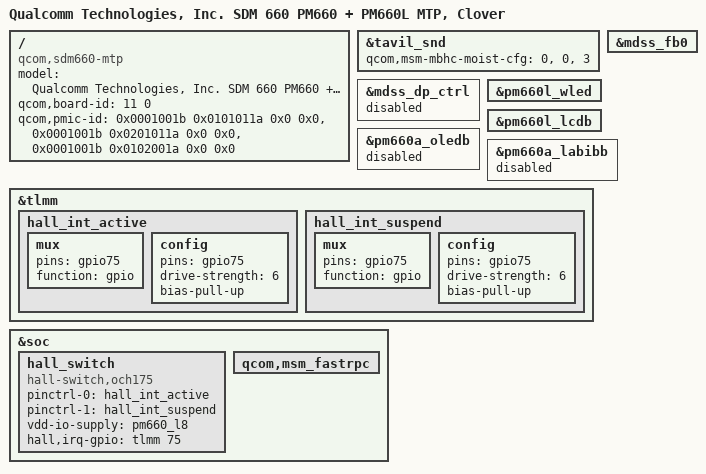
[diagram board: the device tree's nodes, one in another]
/dts-v1/;

#include "sdm660.dtsi"
#include "sdm660-mtp.dtsi"
#include "sdm660-mtp-clover.dtsi"
#include "sdm660-internal-codec.dtsi"

/ {
	model = "Qualcomm Technologies, Inc. SDM 660 PM660 + PM660L MTP, Clover";
	compatible = "qcom,sdm660-mtp", "qcom,sdm660", "qcom,mtp";
	qcom,board-id = <11 0>;
	qcom,pmic-id = <0x0001001b 0x0101011a 0x0 0x0>,
			<0x0001001b 0x0201011a 0x0 0x0>,
			<0x0001001b 0x0102001a 0x0 0x0>;
};

&tavil_snd {
	qcom,msm-mbhc-moist-cfg = <0>, <0>, <3>;
};

&mdss_dp_ctrl {
	status="disabled";
};

&mdss_fb0 {
	/delete-property/ qcom,mdss-mixer-swap;
};

/* Enable WLED */
&pm660l_wled {
	status = "okay";
};

/* Enable LCDB */
&pm660l_lcdb {
	status = "okay";
};

/* Disable OLEDB */
&pm660a_oledb {
	status = "disabled";
};

/* Disable LABIBB */
&pm660a_labibb {
	status = "disable";
};

&tlmm {
	hall_int_active:hall_int_active {
		mux {
			pins = "gpio75";
			function = "gpio";
		};

		config {
			pins = "gpio75";
			drive-strength = <6>;
			bias-pull-up;
		};
	};

	hall_int_suspend: hall_int_suspend {
		mux {
			pins = "gpio75";
			function = "gpio";
		};

		config {
			pins = "gpio75";
			drive-strength = <6>;
			bias-pull-up;
		};
	};
};

&soc {
	hall_switch {
		compatible = "hall-switch,och175";
		pinctrl-names = "hall_active","hall_suspend";
		pinctrl-0 = <&hall_int_active>;
		pinctrl-1 = <&hall_int_suspend>;
		vdd-io-supply= <&pm660_l8>;
		interrupt-names = "hall_irq";
		hall,irq-gpio = <&tlmm 75 0x0>;
	};

	/* Disable fastrpc sensors PDR */
	qcom,msm_fastrpc {
		/delete-property/ qcom,fastrpc-adsp-sensors-pdr;
	};
};
